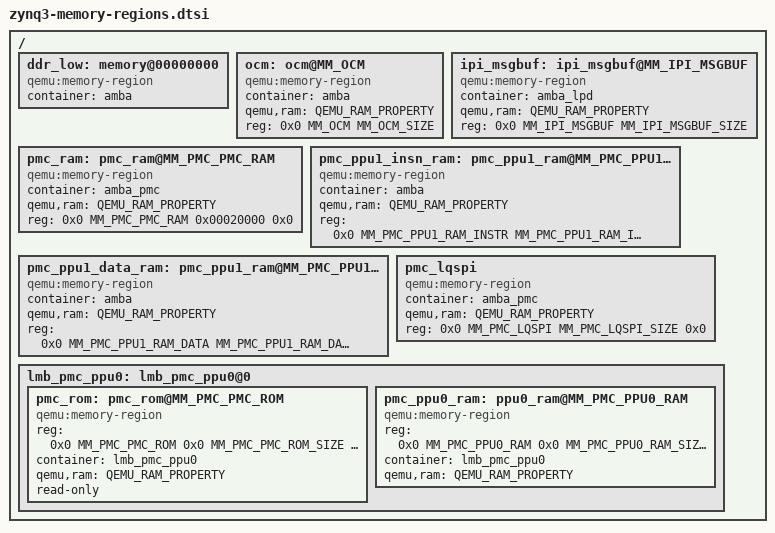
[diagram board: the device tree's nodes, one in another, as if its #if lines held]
/*
 * Zynq3 memory region include file
 *
 * Copyright (c) 2016, Xilinx Inc
 * All rights reserved.
 *
 * Redistribution and use in source and binary forms, with or without
 * modification, are permitted provided that the following conditions are met:
 *     * Redistributions of source code must retain the above copyright
 *       notice, this list of conditions and the following disclaimer.
 *     * Redistributions in binary form must reproduce the above copyright
 *       notice, this list of conditions and the following disclaimer in the
 *       documentation and/or other materials provided with the distribution.
 *     * Neither the name of the <organization> nor the
 *       names of its contributors may be used to endorse or promote products
 *       derived from this software without specific prior written permission.
 *
 * THIS SOFTWARE IS PROVIDED BY THE COPYRIGHT HOLDERS AND CONTRIBUTORS "AS IS" AND
 * ANY EXPRESS OR IMPLIED WARRANTIES, INCLUDING, BUT NOT LIMITED TO, THE IMPLIED
 * WARRANTIES OF MERCHANTABILITY AND FITNESS FOR A PARTICULAR PURPOSE ARE
 * DISCLAIMED. IN NO EVENT SHALL <COPYRIGHT HOLDER> BE LIABLE FOR ANY
 * DIRECT, INDIRECT, INCIDENTAL, SPECIAL, EXEMPLARY, OR CONSEQUENTIAL DAMAGES
 * (INCLUDING, BUT NOT LIMITED TO, PROCUREMENT OF SUBSTITUTE GOODS OR SERVICES;
 * LOSS OF USE, DATA, OR PROFITS; OR BUSINESS INTERRUPTION) HOWEVER CAUSED AND
 * ON ANY THEORY OF LIABILITY, WHETHER IN CONTRACT, STRICT LIABILITY, OR TORT
 * (INCLUDING NEGLIGENCE OR OTHERWISE) ARISING IN ANY WAY OUT OF THE USE OF THIS
 * SOFTWARE, EVEN IF ADVISED OF THE POSSIBILITY OF SUCH DAMAGE.
 */

#include "zynq3.dtsh"

/ {
	ddr_low: memory@00000000 {
		compatible = "qemu:memory-region";
		device_type = "memory";
		container = <&amba>;
	};

	/* FIXME: This should be located in the PS.  */
	ocm: ocm@MM_OCM {
		compatible = "qemu:memory-region";
		device_type = "memory";
		container = <&amba>;
		qemu,ram = <QEMU_RAM_PROPERTY>;
		reg = <0x0 MM_OCM MM_OCM_SIZE>;
	};

	ipi_msgbuf: ipi_msgbuf@MM_IPI_MSGBUF {
		compatible = "qemu:memory-region";
		device_type = "memory";
		container = <&amba_lpd>;
		qemu,ram = <QEMU_RAM_PROPERTY>;
		reg = <0x0 MM_IPI_MSGBUF MM_IPI_MSGBUF_SIZE>;
	};

	pmc_ram: pmc_ram@MM_PMC_PMC_RAM {
		compatible = "qemu:memory-region";
		container = <&amba_pmc>;
		qemu,ram = <QEMU_RAM_PROPERTY>;
		reg = <0x0 MM_PMC_PMC_RAM 0x00020000 0x0>;
	};

	pmc_ppu1_insn_ram: pmc_ppu1_ram@MM_PMC_PPU1_RAM_INSTR {
		compatible = "qemu:memory-region";
		container = <&amba>;
		qemu,ram = <QEMU_RAM_PROPERTY>;
		reg = <0x0 MM_PMC_PPU1_RAM_INSTR MM_PMC_PPU1_RAM_INSTR_SIZE 0x0>;
	};

	pmc_ppu1_data_ram: pmc_ppu1_ram@MM_PMC_PPU1_RAM_DATA {
		compatible = "qemu:memory-region";
		container = <&amba>;
		qemu,ram = <QEMU_RAM_PROPERTY>;
		reg = <0x0 MM_PMC_PPU1_RAM_DATA MM_PMC_PPU1_RAM_DATA_SIZE 0x0>;
	};

#ifdef LQSPI_XIP
	pmc_lqspi {
		device_type = "memory";
		compatible = "qemu:memory-region";
		container = <&amba_pmc>;
		qemu,ram = <QEMU_RAM_PROPERTY>;
		reg = <0x0 MM_PMC_LQSPI MM_PMC_LQSPI_SIZE 0x0>;
	};
#endif

	lmb_pmc_ppu0: lmb_pmc_ppu0@0 {
		/* PMC ROM. 128K.  */
		pmc_rom: pmc_rom@MM_PMC_PMC_ROM {
			reg = <0x0 MM_PMC_PMC_ROM 0x0 MM_PMC_PMC_ROM_SIZE 0x1>;
			compatible = "qemu:memory-region";
			container = <&lmb_pmc_ppu0>;
			qemu,ram = <QEMU_RAM_PROPERTY>;
			read-only;
		};

		/* PMC PPU0 RAM. 8K.  */
		pmc_ppu0_ram: ppu0_ram@MM_PMC_PPU0_RAM {
			reg = <0x0 MM_PMC_PPU0_RAM 0x0 MM_PMC_PPU0_RAM_SIZE 0x1>;
			compatible = "qemu:memory-region";
			container = <&lmb_pmc_ppu0>;
			qemu,ram = <QEMU_RAM_PROPERTY>;
		};
	};
};
